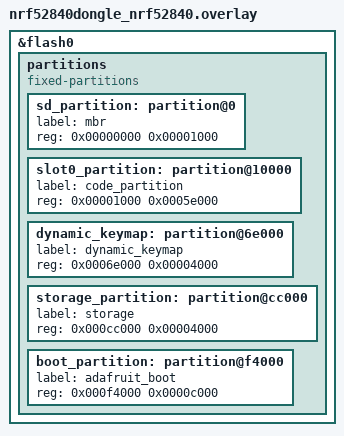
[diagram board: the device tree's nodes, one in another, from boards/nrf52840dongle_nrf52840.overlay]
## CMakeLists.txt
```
cmake_minimum_required(VERSION 3.20.0)

add_compile_definitions(MATRIX_COLS=CONFIG_MATRIX_COLS)
add_compile_definitions(MATRIX_ROWS=CONFIG_MATRIX_ROWS)
add_compile_definitions(MAX_LAYER=CONFIG_MAX_LAYER)
add_compile_definitions(RAW_ENABLE=CONFIG_RAW_ENABLE)
add_compile_definitions(KEYBOARD_SHARED_EP)
add_compile_definitions(MOUSE_ENABLE=CONFIG_MOUSE_ENABLE)
add_compile_definitions(MOUSE_SHARED_EP)
add_compile_definitions(MOUSEKEY_ENABLE=CONFIG_MOUSE_ENABLE)
add_compile_definitions(EXTRAKEY_ENABLE=CONFIG_EXTRAKEY_ENABLE)
add_compile_definitions(KEYMAP_C="keymap.h")
add_compile_definitions(PERMISSIVE_HOLD)
add_compile_definitions(IGNORE_MOD_TAP_INTERRUPT)
add_compile_definitions(TAPPING_TOGGLE=2)

find_package(Zephyr REQUIRED HINTS $ENV{ZEPHYR_BASE})
project(qmk_on_zephyr)

target_compile_definitions_ifdef(CONFIG_VIA_ENABLE app PRIVATE VIA_ENABLE)
target_compile_definitions_ifdef(CONFIG_VIA_ENABLE app PRIVATE
                                 DYNAMIC_KEYMAP_ENABLE)
target_compile_definitions_ifdef(CONFIG_VIA_ENABLE app PRIVATE EEPROM_DRIVER)
if(${CONFIG_VIA_ENABLE})
  add_compile_definitions(QMK_BUILDDATE="2024-01-12-20:36:00")
  add_compile_definitions(TOTAL_EEPROM_BYTE_COUNT=1024)
endif()
if(${CONFIG_VIA_ENABLE})
  add_compile_definitions(SWAP_HANDS_ENABLE)
endif()

target_include_directories(
  app
  PRIVATE include
          include/platforms/zephyr
          include/logging
          include/keyboard
          lib/qmk_firmware/tmk_core/protocol
          lib/qmk_firmware/quantum
          lib/qmk_firmware/drivers/eeprom
          lib/qmk_firmware/quantum/audio
          lib/qmk_firmware/quantum/bootmagic
          lib/qmk_firmware/quantum/logging
          lib/qmk_firmware/quantum/keymap_extras
          lib/qmk_firmware/quantum/process_keycode
          lib/qmk_firmware/quantum/sequencer
          lib/qmk_firmware/quantum/send_string
          lib/qmk_firmware/platforms)

target_sources(
  app
  PRIVATE src/main.c
          src/protocol.c
          src/timer.c
          src/keymap.c
          src/matrix.c
          src/host.c
          src/bootloader.c
          src/usb_main.c
          src/phoenix_pro/via_custom.c
          lib/qmk_firmware/tmk_core/protocol/report.c
          lib/qmk_firmware/tmk_core/protocol/usb_device_state.c
          lib/qmk_firmware/quantum/quantum.c
          lib/qmk_firmware/quantum/keyboard.c
          lib/qmk_firmware/quantum/led.c
          lib/qmk_firmware/quantum/action.c
          lib/qmk_firmware/quantum/action_util.c
          lib/qmk_firmware/quantum/action_layer.c
          lib/qmk_firmware/quantum/action_tapping.c
          lib/qmk_firmware/quantum/action_tapping.c
          lib/qmk_firmware/quantum/keymap_common.c
          lib/qmk_firmware/quantum/keycode_config.c
          lib/qmk_firmware/quantum/eeconfig.c
          lib/qmk_firmware/quantum/bitwise.c
          lib/qmk_firmware/quantum/matrix_common.c
          lib/qmk_firmware/quantum/debounce/none.c
          lib/qmk_firmware/quantum/logging/print.c
          lib/qmk_firmware/quantum/logging/sendchar.c
          lib/qmk_firmware/quantum/logging/debug.c
          lib/qmk_firmware/quantum/mousekey.c
          lib/qmk_firmware/quantum/bootmagic/magic.c)

add_subdirectory(src/split)

target_sources_ifdef(
  CONFIG_VIA_ENABLE app PRIVATE src/eeprom_emulated_flash.c
  lib/qmk_firmware/quantum/via.c
  lib/qmk_firmware/drivers/eeprom/eeprom_driver.c
  lib/qmk_firmware/quantum/dynamic_keymap.c
  lib/qmk_firmware/quantum/send_string.c)
```

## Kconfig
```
rsource "Kconfig.qmk_on_zephyr"

source "Kconfig.zephyr"
rsource "src/split/Kconfig"
```

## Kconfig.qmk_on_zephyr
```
config MATRIX_COLS
    int "Number of columns in the matrix" 

config MATRIX_ROWS
    int "Number of rows in the matrix"

config MAX_LAYER
    int "Maximum number of keymap layers"

config RAW_ENABLE
    bool "Enable raw HID"

config MOUSE_ENABLE
    bool "Enable mouse"

config EXTRAKEY_ENABLE
    bool "Enable system and consumer key"

config VIA_ENABLE
    bool "Enable VIA"

config FEE_PAGE_SIZE 
    int "Flash page size in MCU. Used when emulating EEPROM"

config FEE_PAGE_COUNT 
    int "Flash page count. Used when emulating EEPROM"

config SWAP_HANDS_ENABLE
    bool "Enable swap hands"
```

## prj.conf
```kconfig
CONFIG_USB_DEVICE_STACK=y
CONFIG_USB_DEVICE_HID=y
CONFIG_USB_HID_DEVICE_COUNT=2
CONFIG_USB_DEVICE_PRODUCT="Phoenix-Pro"
CONFIG_USB_DEVICE_MANUFACTURER="ErgoKB"

CONFIG_MATRIX_COLS=7
CONFIG_MATRIX_ROWS=10
CONFIG_MAX_LAYER=8
CONFIG_MOUSE_ENABLE=y
CONFIG_VIA_ENABLE=y
CONFIG_RAW_ENABLE=y
CONFIG_EXTRAKEY_ENABLE=y
CONFIG_USB_DEVICE_VID=0x1209
CONFIG_USB_DEVICE_PID=0x2304

CONFIG_USB_DEVICE_SOF=y
CONFIG_USB_HID_REPORTS=1
CONFIG_ENABLE_HID_INT_OUT_EP=y

CONFIG_GPIO=y
CONFIG_LOG=n

CONFIG_QMK_ON_ZEPHYR_SPLIT_BLE=y
CONFIG_ZMK_BLE_SPLIT_PERIPHERAL_COUNT=2
CONFIG_BT_MAX_CONN=6
CONFIG_BT_MAX_PAIRED=6
```

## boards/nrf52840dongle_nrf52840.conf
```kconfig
CONFIG_LOG_MODE_IMMEDIATE=y
CONFIG_SERIAL=y
CONFIG_CONSOLE=y
CONFIG_UART_CONSOLE=y

CONFIG_USE_DT_CODE_PARTITION=n
CONFIG_FLASH=y
CONFIG_FLASH_PAGE_LAYOUT=y
CONFIG_FLASH_MAP=y
CONFIG_MPU_ALLOW_FLASH_WRITE=y
CONFIG_NVS=y
CONFIG_SOC_FLASH_NRF_EMULATE_ONE_BYTE_WRITE_ACCESS=y
CONFIG_FEE_PAGE_SIZE=4096
CONFIG_FEE_PAGE_COUNT=1
CONFIG_BT_FILTER_ACCEPT_LIST=y

CONFIG_BUILD_OUTPUT_UF2=y
```

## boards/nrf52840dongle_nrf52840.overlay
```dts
&flash0 {
	/delete-node/ partitions;

	partitions {
		compatible = "fixed-partitions";
		#address-cells = <1>;
		#size-cells = <1>;

		sd_partition: partition@0 {
			label = "mbr";
			reg = <0x00000000 0x00001000>;
		};
		slot0_partition: partition@10000 {
			label = "code_partition";
			reg = <0x00001000 0x0005e000>;
		};
		dynamic_keymap: partition@6e000 {
			label = "dynamic_keymap";
			reg = <0x0006e000 0x00004000>;
		};
		storage_partition: partition@cc000 {
			label = "storage";
			reg = <0x000cc000 0x00004000>;
		};
		boot_partition: partition@f4000 {
			label = "adafruit_boot";
			reg = <0x000f4000 0x0000c000>;
		};
	};
};
```

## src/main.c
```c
#include <zephyr/kernel.h>
#include <zephyr/logging/log.h>
LOG_MODULE_REGISTER(qmk_on_zephyr);

#include "keyboard.h"

void platform_setup(void);

void protocol_setup(void);
void protocol_pre_init(void);
void protocol_post_init(void);
void protocol_pre_task(void);
void protocol_post_task(void);

// Bodge as refactoring this area sucks....
void protocol_init(void) __attribute__((weak));
void protocol_init(void) {
    protocol_pre_init();

    keyboard_init();

    protocol_post_init();
}

void protocol_task(void) __attribute__((weak));
void protocol_task(void) {
    protocol_pre_task();

    keyboard_task();

    protocol_post_task();
}

/** \brief Main
 *
 * FIXME: Needs doc
 */
int main(void) __attribute__((weak));
int main(void) {
    platform_setup();
    protocol_setup();
    keyboard_setup();

    protocol_init();

    /* Main loop */
    while (true) {
        protocol_task();

#ifdef QUANTUM_PAINTER_ENABLE
        // Run Quantum Painter task
        void qp_internal_task(void);
        qp_internal_task();
#endif

#ifdef DEFERRED_EXEC_ENABLE
        // Run deferred executions
        void deferred_exec_task(void);
        deferred_exec_task();
#endif // DEFERRED_EXEC_ENABLE

        housekeeping_task();
    }
}
```

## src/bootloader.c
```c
// TODO (lschyi): implement mcu_reset
void mcu_reset(void) {}

// TODO (lschyi): implement bootloader_jump
void bootloader_jump(void) {}
```

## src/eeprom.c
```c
#include <stdint.h>
#include <stdlib.h>

// TODO (lschyi): implement eeprom function
uint8_t eeprom_read_byte(const uint8_t *__p) { return 0; }
uint16_t eeprom_read_word(const uint16_t *__p) { return 0; }
uint32_t eeprom_read_dword(const uint32_t *__p) { return 0; }
void eeprom_read_block(void *__dst, const void *__src, size_t __n) {}
void eeprom_write_byte(uint8_t *__p, uint8_t __value) {}
void eeprom_write_word(uint16_t *__p, uint16_t __value) {}
void eeprom_write_dword(uint32_t *__p, uint32_t __value) {}
void eeprom_write_block(const void *__src, void *__dst, size_t __n) {}
void eeprom_update_byte(uint8_t *__p, uint8_t __value) {}
void eeprom_update_word(uint16_t *__p, uint16_t __value) {}
void eeprom_update_dword(uint32_t *__p, uint32_t __value) {}
void eeprom_update_block(const void *__src, void *__dst, size_t __n) {}
```

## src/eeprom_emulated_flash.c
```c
/*
 * This software is experimental and a work in progress.
 * Under no circumstances should these files be used in relation to any critical system(s).
 * Use of these files is at your own risk.
 *
 * THE SOFTWARE IS PROVIDED "AS IS", WITHOUT WARRANTY OF ANY KIND, EXPRESS OR IMPLIED,
 * INCLUDING BUT NOT LIMITED TO THE WARRANTIES OF MERCHANTABILITY, FITNESS FOR A PARTICULAR
 * PURPOSE AND NONINFRINGEMENT. IN NO EVENT SHALL THE AUTHORS OR COPYRIGHT HOLDERS BE
 * LIABLE FOR ANY CLAIM, DAMAGES OR OTHER LIABILITY, WHETHER IN AN ACTION OF CONTRACT,
 * TORT OR OTHERWISE, ARISING FROM, OUT OF OR IN CONNECTION WITH THE SOFTWARE OR THE USE OR OTHER
 * DEALINGS IN THE SOFTWARE.
 *
 * This files are free to use from http://engsta.com/stm32-flash-memory-eeprom-emulator/ by
 * Artur F.
 *
 * Modifications for QMK and STM32F303 by Yiancar
 * Modifications to add flash wear leveling by Ilya Zhuravlev
 * Modifications to increase flash density by Don Kjer
 */

#include "eeprom_emulated_flash.h"

#include <stdio.h>
#include <stdbool.h>
#include <stdint.h>
#include <zephyr/drivers/flash.h>
#include <zephyr/logging/log.h>
#include <zephyr/storage/flash_map.h>
LOG_MODULE_REGISTER(emulated_eeprom, 3);

/*
 * We emulate eeprom by writing a snapshot compacted view of eeprom contents,
 * followed by a write log of any change since that snapshot:
 *
 * === SIMULATED EEPROM CONTENTS ===
 *
 * ┌─ Compacted ┬ Write Log ─┐
 * │............│[BYTE][BYTE]│
 * │FFFF....FFFF│[WRD0][WRD1]│
 * │FFFFFFFFFFFF│[WORD][NEXT]│
 * │....FFFFFFFF│[BYTE][WRD0]│
 * ├────────────┼────────────┤
 * └──PAGE_BASE │            │
 *    PAGE_LAST─┴─WRITE_BASE │
 *                WRITE_LAST ┘
 *
 * Compacted contents are the 1's complement of the actual EEPROM contents.
 * e.g. An 'FFFF' represents a '0000' value.
 *
 * The size of the 'compacted' area is equal to the size of the 'emulated' eeprom.
 * The size of the compacted-area and write log are configurable, and the combined
 * size of Compacted + WriteLog is a multiple FEE_PAGE_SIZE, which is MCU dependent.
 * Simulated Eeprom contents are located at the end of available flash space.
 *
 * The following configuration defines can be set:
 *
 * FEE_PAGE_COUNT   # Total number of pages to use for eeprom simulation (Compact + Write log)
 * FEE_DENSITY_BYTES   # Size of simulated eeprom. (Defaults to half the space allocated by FEE_PAGE_COUNT)
 * NOTE: The current implementation does not include page swapping,
 * and FEE_DENSITY_BYTES will consume that amount of RAM as a cached view of actual EEPROM contents.
 *
 * The maximum size of FEE_DENSITY_BYTES is currently 16384. The write log size equals
 * FEE_PAGE_COUNT * FEE_PAGE_SIZE - FEE_DENSITY_BYTES.
 * The larger the write log, the less frequently the compacted area needs to be rewritten.
 *
 *
 * *** General Algorithm ***
 *
 * During initialization:
 * The contents of the Compacted-flash area are loaded and the 1's complement value
 * is cached into memory (e.g. 0xFFFF in Flash represents 0x0000 in cache).
 * Write log entries are processed until a 0xFFFF is reached.
 * Each log entry updates a byte or word in the cache.
 *
 * During reads:
 * EEPROM contents are given back directly from the cache in memory.
 *
 * During writes:
 * The contents of the cache is updated first.
 * If the Compacted-flash area corresponding to the write address is unprogrammed, the 1's complement of the value is written directly into Compacted-flash
 * Otherwise:
 * If the write log is full, erase both the Compacted-flash area and the Write log, then write cached contents to the Compacted-flash area.
 * Otherwise a Write log entry is constructed and appended to the next free position in the Write log.
 *
 *
 * *** Write Log Structure ***
 *
 * Write log entries allow for optimized byte writes to addresses below 128. Writing 0 or 1 words are also optimized when word-aligned.
 *
 * === WRITE LOG ENTRY FORMATS ===
 *
 * ╔═══ Byte-Entry ══╗
 * ║0XXXXXXX║YYYYYYYY║
 * ║ └──┬──┘║└──┬───┘║
 * ║ Address║ Value  ║
 * ╚════════╩════════╝
 * 0 <= Address < 0x80 (128)
 *
 * ╔ Word-Encoded 0 ╗
 * ║100XXXXXXXXXXXXX║
 * ║  │└─────┬─────┘║
 * ║  │Address >> 1 ║
 * ║  └── Value: 0  ║
 * ╚════════════════╝
 * 0 <= Address <= 0x3FFE (16382)
 *
 * ╔ Word-Encoded 1 ╗
 * ║101XXXXXXXXXXXXX║
 * ║  │└─────┬─────┘║
 * ║  │Address >> 1 ║
 * ║  └── Value: 1  ║
 * ╚════════════════╝
 * 0 <= Address <= 0x3FFE (16382)
 *
 * ╔═══ Reserved ═══╗
 * ║110XXXXXXXXXXXXX║
 * ╚════════════════╝
 *
 * ╔═══════════ Word-Next ═══════════╗
 * ║111XXXXXXXXXXXXX║YYYYYYYYYYYYYYYY║
 * ║   └─────┬─────┘║└───────┬──────┘║
 * ║(Address-128)>>1║     ~Value     ║
 * ╚════════════════╩════════════════╝
 * (  0 <= Address <  0x0080 (128): Reserved)
 * 0x80 <= Address <= 0x3FFE (16382)
 *
 * Write Log entry ranges:
 * 0x0000 ... 0x7FFF - Byte-Entry;     address is (Entry & 0x7F00) >> 4; value is (Entry & 0xFF)
 * 0x8000 ... 0x9FFF - Word-Encoded 0; address is (Entry & 0x1FFF) << 1; value is 0
 * 0xA000 ... 0xBFFF - Word-Encoded 1; address is (Entry & 0x1FFF) << 1; value is 1
 * 0xC000 ... 0xDFFF - Reserved
 * 0xE000 ... 0xFFBF - Word-Next;      address is (Entry & 0x1FFF) << 1 + 0x80; value is ~(Next_Entry)
 * 0xFFC0 ... 0xFFFE - Reserved
 * 0xFFFF            - Unprogrammed
 *
 */

/* These bits are used for optimizing encoding of bytes, 0 and 1 */
#define FEE_WORD_ENCODING 0x8000
#define FEE_VALUE_NEXT 0x6000
#define FEE_VALUE_RESERVED 0x4000
#define FEE_VALUE_ENCODED 0x2000
#define FEE_BYTE_RANGE 0x80

/* Flash word value after erase */
#define FEE_EMPTY_WORD ((uint16_t)0xFFFF)

#if !defined(FEE_PAGE_SIZE) || !defined(FEE_PAGE_COUNT)
#    error "not implemented."
#endif

/* In-memory contents of emulated eeprom for faster access */
/* *TODO: Implement page swapping */
static uint16_t WordBuf[FEE_DENSITY_BYTES / 2];
static uint8_t *DataBuf = (uint8_t *)WordBuf;

/* Pointer to the first available slot within the write log */
static uint16_t *empty_slot;

#define KEYMAP_PARTITION dynamic_keymap
#define KEYMAP_PARTITION_OFFSET FIXED_PARTITION_OFFSET(KEYMAP_PARTITION)
#define KEYMAP_PARTITION_DEVICE FIXED_PARTITION_DEVICE(KEYMAP_PARTITION)

static const struct device *flash_dev = KEYMAP_PARTITION_DEVICE;

// #define DEBUG_EEPROM_OUTPUT

/*
 * Debug print utils
 */

#if defined(DEBUG_EEPROM_OUTPUT)

#    define debug_eeprom debug_enable
#    define eeprom_println(s) println(s)
#    define eeprom_printf(fmt, ...) xprintf(fmt, ##__VA_ARGS__);

#else /* NO_DEBUG */

#    define debug_eeprom false
#    define eeprom_println(s)
#    define eeprom_printf(fmt, ...)

#endif /* NO_DEBUG */

void print_eeprom(void) {
#ifndef NO_DEBUG
    int empty_rows = 0;
    for (uint16_t i = 0; i < FEE_DENSITY_BYTES; i++) {
        if (i % 16 == 0) {
            if (i >= FEE_DENSITY_BYTES - 16) {
                /* Make sure we display the last row */
                empty_rows = 0;
            }
            /* Check if this row is uninitialized */
            ++empty_rows;
            for (uint16_t j = 0; j < 16; j++) {
                if (DataBuf[i + j]) {
                    empty_rows = 0;
                    break;
                }
            }
            if (empty_rows > 1) {
                /* Repeat empty row */
                if (empty_rows == 2) {
                    /* Only display the first repeat empty row */
                    LOG_INF("*");
                }
                i += 15;
                continue;
            }
            LOG_INF("%04x", i);
        }
        if (i % 8 == 0) LOG_INF(" ");

        LOG_INF(" %02x", DataBuf[i]);
        if ((i + 1) % 16 == 0) {
            LOG_INF("");
        }
    }
#endif
}

static int read_from_flash(uint32_t start, void *data, size_t len) {
    uint32_t offset = KEYMAP_PARTITION_OFFSET + start;
    return flash_read(flash_dev, offset, data, len);
}

static int write_to_flash(uint32_t start, const void *data, size_t len) {
    LOG_DBG("Really writing to 0x%x with 0x%x", start, *(uint16_t *)data);
    uint32_t offset = KEYMAP_PARTITION_OFFSET + start;
    return flash_write(flash_dev, offset, data, len);
}

static int erase_flash(uint32_t start, size_t len) {
    uint32_t offset = KEYMAP_PARTITION_OFFSET + start;
    return flash_erase(flash_dev, offset, len);
}

uint16_t EEPROM_Init(void) {
    /* Load emulated eeprom contents from compacted flash into memory */
    uint16_t *src  = (uint16_t *)FEE_COMPACTED_BASE_ADDRESS;
    uint16_t *dest = (uint16_t *)DataBuf;
    for (; src < (uint16_t *)FEE_COMPACTED_LAST_ADDRESS; ++src, ++dest) {
        uint16_t val;
        if (read_from_flash(src, &val, 2)) {
            LOG_ERR("Failed to load original content from flash");
        }
        *dest = ~val;
    }

    if (debug_eeprom) {
        LOG_DBG("EEPROM_Init Compacted Pages:");
        print_eeprom();
        LOG_DBG("EEPROM_Init Write Log:");
    }

    /* Replay write log */
    uint16_t *log_addr;
    for (log_addr = (uint16_t *)FEE_WRITE_LOG_BASE_ADDRESS; log_addr < (uint16_t *)FEE_WRITE_LOG_LAST_ADDRESS; ++log_addr) {
        uint16_t address;
        if (read_from_flash(log_addr, &address, 2)) {
            LOG_ERR("Failed to load next write log!");
        }
        LOG_DBG("address = 0x%x", address);
        if (address == FEE_EMPTY_WORD) {
            break;
        }
        /* Check for lowest 128-bytes optimization */
        if (!(address & FEE_WORD_ENCODING)) {
            uint8_t bvalue = (uint8_t)address;
            address >>= 8;
            DataBuf[address] = bvalue;
            eeprom_printf("DataBuf[0x%02x] = 0x%02x;\n", address, bvalue);
        } else {
            uint16_t wvalue;
            /* Check if value is in next word */
            if ((address & FEE_VALUE_NEXT) == FEE_VALUE_NEXT) {
                /* Read value from next word */
                if (++log_addr >= (uint16_t *)FEE_WRITE_LOG_LAST_ADDRESS) {
                    break;
                }
                if (read_from_flash(log_addr, &wvalue, 2)) {
                    LOG_DBG("Failed to load word-next!");
                }
                LOG_DBG("next wvlaue = 0x%x", wvalue);
                wvalue = ~wvalue;
                if (!wvalue) {
                    eeprom_printf("Incomplete write at log_addr: 0x%04lx;\n", (uint32_t)log_addr);
                    /* Possibly incomplete write.  Ignore and continue */
                    continue;
                }
                address &= 0x1FFF;
                address <<= 1;
                /* Writes to addresses less than 128 are byte log entries */
                address += FEE_BYTE_RANGE;
            } else {
                /* Reserved for future use */
                if (address & FEE_VALUE_RESERVED) {
                    eeprom_printf("Reserved encoded value at log_addr: 0x%04lx;\n", (uint32_t)log_addr);
                    continue;
                }
                /* Optimization for 0 or 1 values. */
                wvalue = (address & FEE_VALUE_ENCODED) >> 13;
                address &= 0x1FFF;
                address <<= 1;
            }
            if (address < FEE_DENSITY_BYTES) {
                eeprom_printf("DataBuf[0x%04x] = 0x%04x;\n", address, wvalue);
                *(uint16_t *)(&DataBuf[address]) = wvalue;
            } else {
                eeprom_printf("DataBuf[0x%04x] cannot be set to 0x%04x [BAD ADDRESS]\n", address, wvalue);
            }
        }
    }

    empty_slot = log_addr;

    if (debug_eeprom) {
        LOG_DBG("EEPROM_Init Final DataBuf:");
        print_eeprom();
    }

    return FEE_DENSITY_BYTES;
}

/* Clear flash contents (doesn't touch in-memory DataBuf) */
static void eeprom_clear(void) {
    if (erase_flash(FEE_COMPACTED_BASE_ADDRESS, FEE_PAGE_COUNT * FEE_PAGE_SIZE)) {
        LOG_ERR("Failed to clear compact and write log in flash!");
    }

    empty_slot = (uint16_t *)FEE_WRITE_LOG_BASE_ADDRESS;
    eeprom_printf("eeprom_clear empty_slot: 0x%08lx\n", (uint32_t)empty_slot);
}

/* Erase emulated eeprom */
void EEPROM_Erase(void) {
    eeprom_println("EEPROM_Erase");
    /* Erase compacted pages and write log */
    eeprom_clear();
    /* re-initialize to reset DataBuf */
    EEPROM_Init();
}

/* Compact write log */
static uint8_t eeprom_compact(void) {
    /* Erase compacted pages and write log */
    eeprom_clear();

    FLASH_Status final_status = FLASH_COMPLETE;

    /* Write emulated eeprom contents from memory to compacted flash */
    for (int i = 0; i < FEE_DENSITY_BYTES / 2; i++) {
        WordBuf[i] = ~WordBuf[i];
    }
    if (write_to_flash(FEE_COMPACTED_BASE_ADDRESS, WordBuf, sizeof(WordBuf))) {
        LOG_ERR("Failed to write compact data to flash!");
    }
    for (int i = 0; i < FEE_DENSITY_BYTES / 2; i++) {
        WordBuf[i] = ~WordBuf[i];
    }

    if (debug_eeprom) {
        LOG_DBG("eeprom_compacted:");
        print_eeprom();
    }

    return final_status;
}

static uint8_t eeprom_write_direct_entry(uint16_t Address) {
    /* Check if we can just write this directly to the compacted flash area */
    uintptr_t directAddress = FEE_COMPACTED_BASE_ADDRESS + (Address & 0xFFFE);
    uint16_t orig_content;
    if (read_from_flash(directAddress, &orig_content, 2)) {
        LOG_ERR("Failed to directly read from flash");
    }
    if (orig_content == FEE_EMPTY_WORD) {
        /* Write the value directly to the compacted area without a log entry */
        uint16_t value = ~*(uint16_t *)(&DataBuf[Address & 0xFFFE]);
        /* Early exit if a write isn't needed */
        if (value == FEE_EMPTY_WORD) return FLASH_COMPLETE;

        eeprom_printf("FLASH_ProgramHalfWord(0x%08lx, 0x%04x) [DIRECT]\n", (uint32_t)directAddress, value);
        if (write_to_flash(directAddress, &value, 2)) {
            LOG_ERR("Failed to directly write to flash");
        }

        return FLASH_COMPLETE;
    }
    return 0;
}

static uint8_t eeprom_write_log_word_entry(uint16_t Address) {
    FLASH_Status final_status = FLASH_COMPLETE;

    uint16_t value = *(uint16_t *)(&DataBuf[Address]);
    eeprom_printf("eeprom_write_log_word_entry(0x%04x): 0x%04x\n", Address, value);

    /* MSB signifies the lowest 128-byte optimization is not in effect */
    uint16_t encoding = FEE_WORD_ENCODING;
    uint8_t  entry_size;
    if (value <= 1) {
        encoding |= value << 13;
        entry_size = 2;
    } else {
        encoding |= FEE_VALUE_NEXT;
        entry_size = 4;
        /* Writes to addresses less than 128 are byte log entries */
        Address -= FEE_BYTE_RANGE;
    }

    /* if we can't find an empty spot, we must compact emulated eeprom */
    if (empty_slot > (uint16_t *)(FEE_WRITE_LOG_LAST_ADDRESS - entry_size)) {
        /* compact the write log into the compacted flash area */
        return eeprom_compact();
    }

    /* Word log writes should be word-aligned.  Take back a bit */
    Address >>= 1;
    Address |= encoding;

    /* ok we found a place let's write our data */
    /* address */
    eeprom_printf("FLASH_ProgramHalfWord(0x%08lx, 0x%04x)\n", (uint32_t)empty_slot, Address);
    if (write_to_flash(empty_slot++, &Address, 2)) {
        LOG_ERR("Failed to write address of word-next write log");
    }
    final_status = FLASH_COMPLETE;

    /* value */
    if (encoding == (FEE_WORD_ENCODING | FEE_VALUE_NEXT)) {
        eeprom_printf("FLASH_ProgramHalfWord(0x%08lx, 0x%04x)\n", (uint32_t)empty_slot, ~value);
        uint16_t write_val = ~value;
        if (write_to_flash(empty_slot++, &write_val, 2)) {
            LOG_ERR("Failed to write value of word-next write log");
        }
    }

    return final_status;
}

static uint8_t eeprom_write_log_byte_entry(uint16_t Address) {
    eeprom_printf("eeprom_write_log_byte_entry(0x%04x): 0x%02x\n", Address, DataBuf[Address]);

    /* if couldn't find an empty spot, we must compact emulated eeprom */
    if (empty_slot >= (uint16_t *)FEE_WRITE_LOG_LAST_ADDRESS) {
        /* compact the write log into the compacted flash area */
        return eeprom_compact();
    }

    /* ok we found a place let's write our data */
    /* Pack address and value into the same word */
    uint16_t value = (Address << 8) | DataBuf[Address];

    /* write to flash */
    eeprom_printf("FLASH_ProgramHalfWord(0x%08lx, 0x%04x)\n", (uint32_t)empty_slot, value);
    if (write_to_flash(empty_slot++, &value, 2)) {
        LOG_ERR("Failed to write byte entry");
    }

    return FLASH_COMPLETE;
}

uint8_t EEPROM_WriteDataByte(uint16_t Address, uint8_t DataByte) {
    /* if the address is out-of-bounds, do nothing */
    if (Address >= FEE_DENSITY_BYTES) {
        eeprom_printf("EEPROM_WriteDataByte(0x%04x, 0x%02x) [BAD ADDRESS]\n", Address, DataByte);
        return FLASH_BAD_ADDRESS;
    }

    /* if the value is the same, don't bother writing it */
    if (DataBuf[Address] == DataByte) {
        eeprom_printf("EEPROM_WriteDataByte(0x%04x, 0x%02x) [SKIP SAME]\n", Address, DataByte);
        return 0;
    }

    /* keep DataBuf cache in sync */
    DataBuf[Address] = DataByte;
    LOG_DBG("Setting [0x%x] = 0x%x", Address, DataByte);
    eeprom_printf("EEPROM_WriteDataByte DataBuf[0x%04x] = 0x%02x\n", Address, DataBuf[Address]);

    /* perform the write into flash memory */
    /* First, attempt to write directly into the compacted flash area */
    FLASH_Status status = eeprom_write_direct_entry(Address);
    if (!status) {
        /* Otherwise append to the write log */
        if (Address < FEE_BYTE_RANGE) {
            status = eeprom_write_log_byte_entry(Address);
        } else {
            status = eeprom_write_log_word_entry(Address & 0xFFFE);
        }
    }
    if (status != 0 && status != FLASH_COMPLETE) {
        eeprom_printf("EEPROM_WriteDataByte [STATUS == %d]\n", status);
    }
    return status;
}

uint8_t EEPROM_WriteDataWord(uint16_t Address, uint16_t DataWord) {
    /* if the address is out-of-bounds, do nothing */
    if (Address >= FEE_DENSITY_BYTES) {
        eeprom_printf("EEPROM_WriteDataWord(0x%04x, 0x%04x) [BAD ADDRESS]\n", Address, DataWord);
        return FLASH_BAD_ADDRESS;
    }

    /* Check for word alignment */
    FLASH_Status final_status = FLASH_COMPLETE;
    if (Address % 2) {
        final_status        = EEPROM_WriteDataByte(Address, DataWord);
        FLASH_Status status = EEPROM_WriteDataByte(Address + 1, DataWord >> 8);
        if (status != FLASH_COMPLETE) final_status = status;
        if (final_status != 0 && final_status != FLASH_COMPLETE) {
            eeprom_printf("EEPROM_WriteDataWord [STATUS == %d]\n", final_status);
        }
        return final_status;
    }

    /* if the value is the same, don't bother writing it */
    uint16_t oldValue = *(uint16_t *)(&DataBuf[Address]);
    if (oldValue == DataWord) {
        eeprom_printf("EEPROM_WriteDataWord(0x%04x, 0x%04x) [SKIP SAME]\n", Address, DataWord);
        return 0;
    }

    /* keep DataBuf cache in sync */
    *(uint16_t *)(&DataBuf[Address]) = DataWord;
    LOG_DBG("Setting [0x%x, 0x%x] = 0x%x", Address, Address+1, DataWord);
    eeprom_printf("EEPROM_WriteDataWord DataBuf[0x%04x] = 0x%04x\n", Address, *(uint16_t *)(&DataBuf[Address]));

    /* perform the write into flash memory */
    /* First, attempt to write directly into the compacted flash area */
    final_status = eeprom_write_direct_entry(Address);
    if (!final_status) {
        LOG_DBG("Cannot write direct entry");
    } else {
        LOG_DBG("Write direct entry");
    }
    if (!final_status) {
        /* Otherwise append to the write log */
        /* Check if we need to fall back to byte write */
        if (Address < FEE_BYTE_RANGE) {
            final_status = FLASH_COMPLETE;
            /* Only write a byte if it has changed */
            if ((uint8_t)oldValue != (uint8_t)DataWord) {
                final_status = eeprom_write_log_byte_entry(Address);
            }
            FLASH_Status status = FLASH_COMPLETE;
            /* Only write a byte if it has changed */
            if ((oldValue >> 8) != (DataWord >> 8)) {
                status = eeprom_write_log_byte_entry(Address + 1);
            }
            if (status != FLASH_COMPLETE) final_status = status;
        } else {
            final_status = eeprom_write_log_word_entry(Address);
        }
    }
    if (final_status != 0 && final_status != FLASH_COMPLETE) {
        eeprom_printf("EEPROM_WriteDataWord [STATUS == %d]\n", final_status);
    }
    return final_status;
}

uint8_t EEPROM_ReadDataByte(uint16_t Address) {
    uint8_t DataByte = 0xFF;

    if (Address < FEE_DENSITY_BYTES) {
        DataByte = DataBuf[Address];
    }

    eeprom_printf("EEPROM_ReadDataByte(0x%04x): 0x%02x\n", Address, DataByte);

    return DataByte;
}

uint16_t EEPROM_ReadDataWord(uint16_t Address) {
    uint16_t DataWord = 0xFFFF;

    if (Address < FEE_DENSITY_BYTES - 1) {
        /* Check word alignment */
        if (Address % 2) {
            DataWord = DataBuf[Address] | (DataBuf[Address + 1] << 8);
        } else {
            DataWord = *(uint16_t *)(&DataBuf[Address]);
        }
    }

    eeprom_printf("EEPROM_ReadDataWord(0x%04x): 0x%04x\n", Address, DataWord);

    return DataWord;
}

/*****************************************************************************
 *  Bind to eeprom_driver.c
 *******************************************************************************/
void eeprom_driver_init(void) {
    if (!device_is_ready(flash_dev)) {
        LOG_ERR("flash device is not ready");
        return;
    }

    EEPROM_Init();
}

void eeprom_driver_erase(void) {
    EEPROM_Erase();
}

void eeprom_read_block(void *buf, const void *addr, size_t len) {
    const uint8_t *src  = (const uint8_t *)addr;
    uint8_t *      dest = (uint8_t *)buf;

    /* Check word alignment */
    if (len && (uintptr_t)src % 2) {
        /* Read the unaligned first byte */
        *dest++ = EEPROM_ReadDataByte((const uintptr_t)src++);
        --len;
    }

    uint16_t value;
    bool     aligned = ((uintptr_t)dest % 2 == 0);
    while (len > 1) {
        value = EEPROM_ReadDataWord((const uintptr_t)((uint16_t *)src));
        if (aligned) {
            *(uint16_t *)dest = value;
            dest += 2;
        } else {
            *dest++ = value;
            *dest++ = value >> 8;
        }
        src += 2;
        len -= 2;
    }
    if (len) {
        *dest = EEPROM_ReadDataByte((const uintptr_t)src);
    }
}

void eeprom_write_block(const void *buf, void *addr, size_t len) {
    uint8_t *      dest = (uint8_t *)addr;
    const uint8_t *src  = (const uint8_t *)buf;

    /* Check word alignment */
    if (len && (uintptr_t)dest % 2) {
        /* Write the unaligned first byte */
        EEPROM_WriteDataByte((uintptr_t)dest++, *src++);
        --len;
    }

    uint16_t value;
    bool     aligned = ((uintptr_t)src % 2 == 0);
    while (len > 1) {
        if (aligned) {
            value = *(uint16_t *)src;
        } else {
            value = *(uint8_t *)src | (*(uint8_t *)(src + 1) << 8);
        }
        EEPROM_WriteDataWord((uintptr_t)((uint16_t *)dest), value);
        dest += 2;
        src += 2;
        len -= 2;
    }

    if (len) {
        EEPROM_WriteDataByte((uintptr_t)dest, *src);
    }
}
```

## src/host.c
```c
#include "host.h"
#include "report.h"
#include "usb_main.h"

#include <stdint.h>

static uint16_t last_system_usage = 0;
static uint16_t last_consumer_usage = 0;
// TODO (lschyi): should return driver keyboard leds
uint8_t host_keyboard_leds(void) { return 0; }

void host_keyboard_send(report_keyboard_t *report) {
  zephyr_driver.send_keyboard(report);
}

void host_mouse_send(report_mouse_t *report) {
  zephyr_driver.send_mouse(report);
}

void host_system_send(uint16_t usage) {
  if (usage == last_system_usage)
    return;
  last_system_usage = usage;

  zephyr_driver.send_system(usage);
}

void host_consumer_send(uint16_t usage) {
  if (usage == last_consumer_usage)
    return;
  last_consumer_usage = usage;

  zephyr_driver.send_consumer(usage);
}
```

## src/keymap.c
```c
#include "quantum_keycodes.h"
#include "keycode.h"
#include "keyboard.h"
#include "keymap.h"

const uint16_t keymaps[][MATRIX_ROWS][MATRIX_COLS] = {
[BASE] = LAYOUT_phoenix(
    KC_ESC,  KC_1,    KC_2,    KC_3,    KC_4,    KC_5,    KC_GRV,
    KC_TAB,  KC_Q,    KC_W,    KC_E,    KC_R,    KC_T,    KC_LCTL,
    KC_LCTL, KC_A,    KC_S,    KC_D,    KC_F,    KC_G,    KC_LSFT,
    KC_LSFT, KC_Z,    KC_X,    KC_C,    KC_V,    KC_B,
                      KC_LSFT, KC_LCTL, KC_LALT,
                                                          KC_VOLD, KC_VOLU,
                                                 KC_SPC,  KC_LGUI, KC_LSFT,

             KC_EQL,  KC_6,    KC_7,    KC_8,    KC_9,    KC_0,    KC_BSPC,
             KC_EQL,  KC_Y,    KC_U,    KC_I,    KC_O,    KC_P,    KC_BSLS,
             KC_MINS, KC_H,    KC_J,    KC_K,    KC_L,    KC_SCLN, KC_QUOT,
                      KC_N,    KC_M,    KC_COMM, KC_DOT,  KC_SLSH, KC_RSFT,
                               KC_SPC,  (QK_TOGGLE_LAYER | ((1)&0xFF)),   QK_TOGGLE_LAYER | ((2)&0xFF),
    KC_F11,  KC_F12,
    KC_ESC,  (QK_MOMENTARY | ((1)&0xFF)),   KC_ENT),
[ARROW] = LAYOUT_phoenix(
    KC_TRNS, KC_TRNS, KC_TRNS, KC_TRNS, KC_TRNS, KC_TRNS, KC_TRNS,
    KC_TRNS, KC_TRNS, KC_TRNS, KC_TRNS, KC_TRNS, KC_TRNS, KC_TRNS,
    KC_TRNS, KC_TRNS, KC_TRNS, KC_TRNS, KC_GRV, KC_GRV,  KC_TRNS,
    KC_TRNS, KC_TRNS, KC_TRNS, KC_TRNS, KC_TRNS, KC_TRNS,
                      KC_TRNS, KC_TRNS, KC_TRNS,
                                                          KC_TRNS, KC_TRNS,
                                                 KC_TRNS, KC_TRNS, KC_TRNS,

             KC_TRNS, KC_TRNS, KC_TRNS, KC_TRNS, KC_TRNS, KC_TRNS, KC_DEL,
             KC_TRNS, KC_TRNS, KC_PGDN, KC_PGUP, KC_LBRC, KC_RBRC, KC_TRNS,
             KC_TRNS, KC_LEFT, KC_DOWN,   KC_UP, KC_RGHT, KC_BSPC, KC_TRNS,
                      KC_TRNS, KC_TRNS, KC_TRNS, KC_TRNS, KC_TRNS, KC_TRNS,
                               KC_TRNS, KC_TRNS, KC_TRNS,
    KC_TRNS,  KC_TRNS,
    KC_TRNS,  KC_TRNS,   KC_TRNS),
[MOUSE] = LAYOUT_phoenix(
    KC_TRNS, KC_TRNS, KC_TRNS, KC_TRNS, KC_TRNS, KC_TRNS, KC_TRNS,
    KC_TRNS, KC_TRNS, KC_TRNS, KC_TRNS, KC_TRNS, KC_TRNS, KC_TRNS,
    KC_TRNS, KC_TRNS, KC_TRNS, KC_TRNS, KC_TRNS, KC_TRNS, KC_TRNS,
    KC_TRNS, KC_TRNS, KC_TRNS, KC_TRNS, KC_TRNS, KC_TRNS,
                      KC_TRNS, KC_TRNS, KC_TRNS,
                                                          KC_TRNS, KC_TRNS,
                                                 KC_BTN1, KC_TRNS, KC_TRNS,

             KC_TRNS, KC_TRNS,       KC_TRNS, KC_TRNS, KC_TRNS, KC_TRNS, KC_TRNS,
             KC_TRNS, KC_MS_WH_DOWN, KC_TRNS, KC_MS_U, KC_TRNS, KC_TRNS, KC_TRNS,
             KC_TRNS, KC_MS_WH_UP,   KC_MS_L, KC_MS_D, KC_MS_R, KC_TRNS, KC_TRNS,
                      KC_TRNS,       KC_TRNS, KC_TRNS, KC_TRNS, KC_TRNS, KC_TRNS,
                                     KC_TRNS, KC_TRNS, KC_TRNS,
    KC_TRNS,  KC_TRNS,
    KC_TRNS,  KC_TRNS,   KC_TRNS),
};

const keypos_t hand_swap_config[MATRIX_ROWS][MATRIX_COLS] = {
    { { 0, 5 }, { 1, 5 }, { 2, 5 }, { 3, 5 }, { 4, 5 }, { 5, 5 }, { 6, 5 } },
    { { 0, 6 }, { 1, 6 }, { 2, 6 }, { 3, 6 }, { 4, 6 }, { 5, 6 }, { 6, 6 } },
    { { 0, 7 }, { 1, 7 }, { 2, 7 }, { 3, 7 }, { 4, 7 }, { 5, 7 }, { 6, 7 } },
    { { 0, 8 }, { 1, 8 }, { 2, 8 }, { 3, 8 }, { 4, 8 }, { 5, 8 }, { 6, 8 } },
    { { 0, 9 }, { 1, 9 }, { 2, 9 }, { 3, 9 }, { 4, 9 }, { 5, 9 }, { 6, 9 } },
    { { 0, 0 }, { 1, 0 }, { 2, 0 }, { 3, 0 }, { 4, 0 }, { 5, 0 }, { 6, 0 } },
    { { 0, 1 }, { 1, 1 }, { 2, 1 }, { 3, 1 }, { 4, 1 }, { 5, 1 }, { 6, 1 } },
    { { 0, 2 }, { 1, 2 }, { 2, 2 }, { 3, 2 }, { 4, 2 }, { 5, 2 }, { 6, 2 } },
    { { 0, 3 }, { 1, 3 }, { 2, 3 }, { 3, 3 }, { 4, 3 }, { 5, 3 }, { 6, 3 } },
    { { 0, 4 }, { 1, 4 }, { 2, 4 }, { 3, 4 }, { 4, 4 }, { 5, 4 }, { 6, 4 } },
};
```

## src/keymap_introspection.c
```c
// Copyright 2022 Nick Brassel (@tzarc)
// SPDX-License-Identifier: GPL-2.0-or-later

// Pull the actual keymap code so that we can inspect stuff from it

// Allow for keymap or userspace rules.mk to specify an alternate location for the keymap array
#ifdef INTROSPECTION_KEYMAP_C
#    include INTROSPECTION_KEYMAP_C
#endif // INTROSPECTION_KEYMAP_C

#include "keycodes.h"
#include "keymap_introspection.h"

////////////////////////////////////////////////////////////////////////////////////////////////////////////////////////
// Key mapping
//
const uint16_t keymaps[][MATRIX_ROWS][MATRIX_COLS] = {};

#define NUM_KEYMAP_LAYERS_RAW ((uint8_t)(sizeof(keymaps) / ((MATRIX_ROWS) * (MATRIX_COLS) * sizeof(uint16_t))))

uint8_t keymap_layer_count_raw(void) {
    return NUM_KEYMAP_LAYERS_RAW;
}

__attribute__((weak)) uint8_t keymap_layer_count(void) {
    return keymap_layer_count_raw();
}

#ifdef DYNAMIC_KEYMAP_ENABLE
_Static_assert(NUM_KEYMAP_LAYERS_RAW <= MAX_LAYER, "Number of keymap layers exceeds maximum set by DYNAMIC_KEYMAP_LAYER_COUNT");
#else
_Static_assert(NUM_KEYMAP_LAYERS_RAW <= MAX_LAYER, "Number of keymap layers exceeds maximum set by LAYER_STATE_(8|16|32)BIT");
#endif

uint16_t keycode_at_keymap_location_raw(uint8_t layer_num, uint8_t row, uint8_t column) {
    if (layer_num < NUM_KEYMAP_LAYERS_RAW && row < MATRIX_ROWS && column < MATRIX_COLS) {
        // TODO (lschyi): fix pgm_read_word
        //return pgm_read_word(&keymaps[layer_num][row][column]);
        return KC_TRNS;
    }
    return KC_TRNS;
}

__attribute__((weak)) uint16_t keycode_at_keymap_location(uint8_t layer_num, uint8_t row, uint8_t column) {
    return keycode_at_keymap_location_raw(layer_num, row, column);
}

////////////////////////////////////////////////////////////////////////////////////////////////////////////////////////
// Encoder mapping

#if defined(ENCODER_ENABLE) && defined(ENCODER_MAP_ENABLE)

#    define NUM_ENCODERMAP_LAYERS_RAW ((uint8_t)(sizeof(encoder_map) / ((NUM_ENCODERS) * (NUM_DIRECTIONS) * sizeof(uint16_t))))

uint8_t encodermap_layer_count_raw(void) {
    return NUM_ENCODERMAP_LAYERS_RAW;
}

__attribute__((weak)) uint8_t encodermap_layer_count(void) {
    return encodermap_layer_count_raw();
}

_Static_assert(NUM_KEYMAP_LAYERS_RAW == NUM_ENCODERMAP_LAYERS_RAW, "Number of encoder_map layers doesn't match the number of keymap layers");

uint16_t keycode_at_encodermap_location_raw(uint8_t layer_num, uint8_t encoder_idx, bool clockwise) {
    if (layer_num < NUM_ENCODERMAP_LAYERS_RAW && encoder_idx < NUM_ENCODERS) {
        return pgm_read_word(&encoder_map[layer_num][encoder_idx][clockwise ? 0 : 1]);
    }
    return KC_TRNS;
}

__attribute__((weak)) uint16_t keycode_at_encodermap_location(uint8_t layer_num, uint8_t encoder_idx, bool clockwise) {
    return keycode_at_encodermap_location_raw(layer_num, encoder_idx, clockwise);
}

#endif // defined(ENCODER_ENABLE) && defined(ENCODER_MAP_ENABLE)

////////////////////////////////////////////////////////////////////////////////////////////////////////////////////////
// Combos

#if defined(COMBO_ENABLE)

uint16_t combo_count_raw(void) {
    return sizeof(key_combos) / sizeof(combo_t);
}
__attribute__((weak)) uint16_t combo_count(void) {
    return combo_count_raw();
}

combo_t* combo_get_raw(uint16_t combo_idx) {
    return &key_combos[combo_idx];
}
__attribute__((weak)) combo_t* combo_get(uint16_t combo_idx) {
    return combo_get_raw(combo_idx);
}

#endif // defined(COMBO_ENABLE)
```

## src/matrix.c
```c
#include "matrix.h"
#include "zmk/split/bluetooth/key_queue.h"

#include <string.h>
#include <zephyr/device.h>
#include <zephyr/kernel.h>

#define ROW_SIZE (sizeof(matrix_row_t) * 8)

matrix_row_t matrix[MATRIX_ROWS];

static matrix_row_t changed_pos[MATRIX_ROWS];

matrix_row_t matrix_get_row(uint8_t row) {
    return matrix[row];
}

void matrix_print(void) {}
void matrix_init(void) {}

uint8_t matrix_scan(void) {
  int32_t events = 0;
  bool changed = false;
  struct key_event ev;
  int err;

  events = k_msgq_num_used_get(&key_queue);
  if (events == 0) {
    return false;
  }

  memset(changed_pos, 0, sizeof(changed_pos));
  for (int i = 0; i < events; i++) {
    err = k_msgq_peek(&key_queue, &ev);
    if (err) {
      return changed;
    }

    int row = ev.position / ROW_SIZE;
    int col = ev.position % ROW_SIZE;
    // if this bit is changed in this loop, do not apply the change, but leave
    // it to the next matrix scan call.
    if (changed_pos[row] & BIT(col)) {
      return changed;
    }
    changed_pos[row] |= BIT(col);

    if (ev.pressed) {
      matrix[row] |= BIT(col);
    } else {
      matrix[row] &= ~((matrix_row_t)BIT(col));
    }

    // In the end, pop the top event.
    k_msgq_get(&key_queue, &ev, K_NO_WAIT);
    changed = true;
  }
  return changed;
}
```

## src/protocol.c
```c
#include "host.h"
#include "report.h"
#include "usb_device_state.h"
#include "usb_main.h"

#include <zephyr/kernel.h>
#include <zephyr/logging/log.h>
LOG_MODULE_DECLARE(qmk_on_zephyr);

void protocol_setup(void) { usb_device_state_init(); }

void protocol_pre_init(void) { init_usb_driver(); }
void protocol_post_init(void) {}

void protocol_pre_task(void) {
#if IS_ENABLED(CONFIG_BT)
  // Proactively yield itself for cooperative multitasking. Give away CPU time
  // for BT and other threads, such that BT SMP can finish pairing.
  k_usleep(1);
#endif /* IS_ENABLED(CONFIG_BT) */
}
void protocol_post_task(void) {
#if CONFIG_RAW_ENABLE
  raw_hid_task();
#endif /* CONFIG_RAW_ENABLE */

#if IS_ENABLED(CONFIG_BT)
  // Proactively yield itself for cooperative multitasking. Give away CPU time
  // for BT and other threads, such that BT SMP can finish pairing.
  k_usleep(1);
#endif /* IS_ENABLED(CONFIG_BT) */
}

void platform_setup(void) {
  // Hardware initialization.
}
```

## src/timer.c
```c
#include "timer.h"

#include <zephyr/kernel.h>

void timer_init(void) {}

uint16_t timer_read(void) { return (uint16_t)k_uptime_get_32(); }

uint32_t timer_read32(void) { return k_uptime_get_32(); }

uint16_t timer_elapsed(uint16_t last) {
  return TIMER_DIFF_16(timer_read(), last);
};

uint32_t timer_elapsed32(uint32_t last) {
  return TIMER_DIFF_32(timer_read32(), last);
};
```

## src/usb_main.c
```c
#include "usb_main.h"
#include "hid.h"
#if CONFIG_RAW_ENABLE
#include "raw_hid.h"
#endif /* CONFIG_RAW_ENABLE */

#include <zephyr/kernel.h>
#include <zephyr/logging/log.h>
#include <zephyr/usb/class/usb_hid.h>
#include <zephyr/usb/usb_device.h>
LOG_MODULE_DECLARE(qmk_on_zephyr);

#define USB_SEND_INTERVAL K_MSEC(10)

typedef union {
  report_keyboard_t keyboard_report;
  report_mouse_t mouse_report;
#if CONFIG_EXTRAKEY_ENABLE
  report_extra_t consume_report;
#endif /* CONFIG_EXTRAKEY_ENABLE */
} hid_report;

enum Report { Keyboard, Mouse, Consumer };

typedef struct {
  enum Report type;
  hid_report report;
} hid_queue_item;

K_MSGQ_DEFINE(hid_report_queue, sizeof(hid_queue_item), 50, 1);

static K_SEM_DEFINE(hid_sem, 1, 1);

static enum usb_dc_status_code usb_status = USB_DC_UNKNOWN;

static const struct device *hid_dev;
static void in_ready_cb(const struct device *dev) { k_sem_give(&hid_sem); }

static const struct hid_ops hid_dev_ops = {
    .int_in_ready = in_ready_cb,
};

static bool via_out_ready = false;
static const struct device *via_dev;
static void via_out_ready_cb(const struct device *dev) { via_out_ready = true; }
static const struct hid_ops via_dev_ops = {
    .int_out_ready = via_out_ready_cb,
};

static void usb_status_cb(enum usb_dc_status_code status,
                          const uint8_t *params) {
  usb_status = status;
}

void init_usb_driver(void) {
  int ret;

  hid_dev = device_get_binding("HID_0");
  if (hid_dev == NULL) {
    LOG_ERR("Cannot get USB HID Device");
    return;
  }
  usb_hid_register_device(hid_dev, hid_kbd_report_desc,
                          sizeof(hid_kbd_report_desc), &hid_dev_ops);
  usb_hid_init(hid_dev);

  via_dev = device_get_binding("HID_1");
  if (via_dev == NULL) {
    LOG_ERR("Cannot get RAW HID Device");
    return;
  }
  usb_hid_register_device(via_dev, via_hid_report_desc,
                          sizeof(via_hid_report_desc), &via_dev_ops);
  usb_hid_init(via_dev);

  ret = usb_enable(usb_status_cb);
  if (ret) {
    LOG_ERR("Failed to enable USB");
    return;
  }
}

static uint8_t keyboard_leds(void) { return 0; };

static int send_report(uint8_t *report, size_t len) {
  switch (usb_status) {
  case USB_DC_SUSPEND:
    return usb_wakeup_request();
  default:
    return hid_int_ep_write(hid_dev, report, len, NULL);
  }
}

static void send_keyboard(report_keyboard_t *report) {
  // TODO (lschyi) handle boot protocol, do not send ep and other things
  report->report_id = 1;
  hid_queue_item item = {.type = Keyboard};
  memcpy(&(item.report), report, sizeof(report_keyboard_t));
  k_msgq_put(&hid_report_queue, &item, K_NO_WAIT);
};

static void send_mouse(report_mouse_t *report) {
  report->report_id = 2;
  k_sem_take(&hid_sem, USB_SEND_INTERVAL);
  int err = send_report((uint8_t *)report, sizeof(report_mouse_t));
  if (err) {
    k_sem_give(&hid_sem);
  }
}

static void send_extra(uint8_t report_id, uint16_t data) {
#if CONFIG_EXTRAKEY_ENABLE
  static report_extra_t report;
  report = (report_extra_t){.report_id = report_id, .usage = data};
  hid_queue_item item = {.type = Consumer};
  memcpy(&(item.report), &report, sizeof(report_extra_t));
  k_msgq_put(&hid_report_queue, &item, K_NO_WAIT);
#endif /* CONFIG_EXTRAKEY_ENABLE */
}

static void send_system(uint16_t usage) {
  send_extra(REPORT_ID_SYSTEM, usage);
}

static void send_consumer(uint16_t usage) {
  send_extra(REPORT_ID_CONSUMER, usage);
}

host_driver_t zephyr_driver = {
    .keyboard_leds = keyboard_leds,
    .send_keyboard = send_keyboard,
    .send_mouse = send_mouse,
    .send_system = send_system,
    .send_consumer = send_consumer,
};

#if CONFIG_RAW_ENABLE
void raw_hid_send(uint8_t *data, uint8_t length) {
  int err = hid_int_ep_write(via_dev, data, length, NULL);
  if (err) {
    LOG_ERR("Failed to write data via raw hid endpoint, err = %d", err);
  }
}

void raw_hid_task(void) {
  static uint8_t buffer[RAW_EPSIZE];
  static uint8_t idx = 0;
  uint32_t size = 0;
  int ret;

  if (!via_out_ready) {
    return;
  }

  do {
    ret = hid_int_ep_read(via_dev, buffer + idx, RAW_EPSIZE, &size);
    if (ret != 0) {
      LOG_ERR("Encounter error while receiving data from raw HID endpoint: %d",
              ret);
      break;
    }
    if (size > 0) {
      idx += size;
      if (idx > RAW_EPSIZE) {
        LOG_ERR("Got RAW HID transaction more thant RAW_EPSIZE(%d) bytes",
                RAW_EPSIZE);
        idx = 0;
        return;
      }
      if (idx == RAW_EPSIZE) {
        raw_hid_receive(buffer, sizeof(buffer));
        idx = 0;
      }
    }
  } while (size > 0);
}
#endif /* CONFIG_RAW_ENABLE */

static void send_report_with_retry(uint8_t *report, size_t len, uint8_t retry) {
  for (uint8_t i = 0; i < retry; i++) {
    if (send_report(report, len) == 0) {
      return;
    }
    k_sleep(USB_SEND_INTERVAL);
  }
}

static void hid_send_worker(void) {
  hid_queue_item item;
  while (true) {
    k_msgq_get(&hid_report_queue, &item, K_FOREVER);
    switch (item.type) {
    case Keyboard:
      send_report_with_retry((uint8_t *)&(item.report.keyboard_report.report_id),
                  KEYBOARD_REPORT_SIZE, 5);
      break;
#if CONFIG_EXTRAKEY_ENABLE
    case Consumer:
      send_report_with_retry((uint8_t *)&(item.report.consume_report),
                  sizeof(report_extra_t), 5);
      break;
#endif /* CONFIG_EXTRAKEY_ENABLE */
    default:
      break;
    }
    // sleep for a small period of time to send next HID package  for some host
    // os will do debounce internally.
    k_sleep(USB_SEND_INTERVAL);
  }
}

K_THREAD_DEFINE(hid_send, 1024, hid_send_worker, NULL, NULL, NULL, 7, 0, 0);
```
